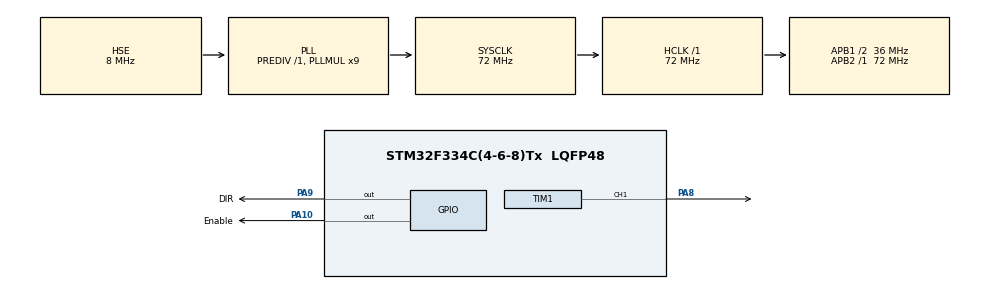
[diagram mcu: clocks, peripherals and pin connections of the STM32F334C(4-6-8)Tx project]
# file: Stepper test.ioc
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Mcu.Family=STM32F3
Mcu.Name=STM32F334C(4-6-8)Tx
Mcu.Package=LQFP48
NVIC.PriorityGroup=NVIC_PRIORITYGROUP_4
NVIC.TIM1_UP_TIM16_IRQn=true\:10\:0\:true\:false\:true\:true\:true\:true
PA10.GPIO_Label=Enable
PA10.Signal=GPIO_Output
PA13.Mode=Serial_Wire
PA13.Signal=SYS_JTMS-SWDIO
PA14.Mode=Serial_Wire
PA14.Signal=SYS_JTCK-SWCLK
PA8.Signal=S_TIM1_CH1
PA9.GPIO_Label=DIR
PA9.Signal=GPIO_Output
PF0\ /\ OSC_IN.Mode=HSE-External-Oscillator
PF0\ /\ OSC_IN.Signal=RCC_OSC_IN
PF1\ /\ OSC_OUT.Mode=HSE-External-Oscillator
PF1\ /\ OSC_OUT.Signal=RCC_OSC_OUT
ProjectManager.HeapSize=0x200
ProjectManager.StackSize=0x400
ProjectManager.TargetToolchain=MDK-ARM V5.32
RCC.AHBFreq_Value=72000000
RCC.APB1CLKDivider=RCC_HCLK_DIV2
RCC.APB1Freq_Value=36000000
RCC.APB1TimFreq_Value=72000000
RCC.APB2Freq_Value=72000000
RCC.APB2TimFreq_Value=72000000
RCC.CortexFreq_Value=72000000
RCC.HCLKFreq_Value=72000000
RCC.HSE_VALUE=8000000
RCC.HSI_VALUE=8000000
RCC.LSE_VALUE=32768
RCC.PLLMUL=RCC_PLL_MUL9
RCC.PLLSourceVirtual=RCC_PLLSOURCE_HSE
RCC.SYSCLKFreq_VALUE=72000000
RCC.SYSCLKSourceVirtual=RCC_SYSCLKSOURCE_PLLCLK
SH.S_TIM1_CH1.0=TIM1_CH1,PWM Generation1 CH1
TIM1.AutoReloadPreload=TIM_AUTORELOAD_PRELOAD_ENABLE
TIM1.Channel-PWM\ Generation1\ CH1=TIM_CHANNEL_1
TIM1.Period=7200
TIM1.Pulse-PWM\ Generation1\ CH1=3600
board=custom

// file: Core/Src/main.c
/* USER CODE BEGIN Header */
/**
  ******************************************************************************
  * @file           : main.c
  * @brief          : Main program body
  ******************************************************************************
  * @attention
  *
  * Copyright (c) 2023 STMicroelectronics.
  * All rights reserved.
  *
  * This software is licensed under terms that can be found in the LICENSE file
  * in the root directory of this software component.
  * If no LICENSE file comes with this software, it is provided AS-IS.
  *
  ******************************************************************************
  */
/* USER CODE END Header */
#include "main.h"
#include "tim.h"
#include "gpio.h"

/* USER CODE BEGIN Includes */
uint16_t Period, Pulse;
uint8_t En, Dir;
uint32_t i_count, steps, start;
uint16_t time;
/* USER CODE END Includes */

void SystemClock_Config(void);

int main(void)
{

  /* MCU Configuration--------------------------------------------------------*/

  /* Reset of all peripherals, Initializes the Flash interface and the Systick. */
  HAL_Init();

  /* Configure the system clock */
  SystemClock_Config();

  /* Initialize all configured peripherals */
  MX_GPIO_Init();
	HAL_GPIO_WritePin(Enable_GPIO_Port, Enable_Pin, GPIO_PIN_SET);
  MX_TIM1_Init();
  /* USER CODE BEGIN 2 */
	Period = 36000;
	time = 200;
  HAL_TIM_Base_Start_IT(&htim1);
  HAL_TIM_PWM_Start(&htim1, TIM_CHANNEL_1);
  /* USER CODE END 2 */

  /* Infinite loop */
  while (1)
  {

		if(start == 1) {
			if(En == 1) {
				HAL_GPIO_WritePin(Enable_GPIO_Port, Enable_Pin, GPIO_PIN_RESET);
			}
			else {
				HAL_GPIO_WritePin(Enable_GPIO_Port, Enable_Pin, GPIO_PIN_SET);
			}

			if(Dir == 1) {
				HAL_GPIO_WritePin(DIR_GPIO_Port, DIR_Pin, GPIO_PIN_RESET);
			}
			else {
				HAL_GPIO_WritePin(DIR_GPIO_Port, DIR_Pin, GPIO_PIN_SET);
			}

			HAL_Delay(time);
			if(Dir == 1) {
				Dir = 0;
			}
			else {
				Dir = 1;
			}

			if(Dir == 1) {
				HAL_GPIO_WritePin(DIR_GPIO_Port, DIR_Pin, GPIO_PIN_RESET);
			}
			else {
				HAL_GPIO_WritePin(DIR_GPIO_Port, DIR_Pin, GPIO_PIN_SET);
			}

			HAL_Delay(time);
			if(Dir == 1) {
				Dir = 0;
			}
			else {
				Dir = 1;
			}

			if(Dir == 1) {
				HAL_GPIO_WritePin(DIR_GPIO_Port, DIR_Pin, GPIO_PIN_RESET);
			}
			else {
				HAL_GPIO_WritePin(DIR_GPIO_Port, DIR_Pin, GPIO_PIN_SET);
			}
		}

		else {
			Dir = 0;
			En = 0;
			HAL_GPIO_WritePin(DIR_GPIO_Port, DIR_Pin, GPIO_PIN_SET);
			HAL_GPIO_WritePin(Enable_GPIO_Port, Enable_Pin, GPIO_PIN_SET);
		}

  }
}

void SystemClock_Config(void)
{
  RCC_OscInitTypeDef RCC_OscInitStruct = {0};
  RCC_ClkInitTypeDef RCC_ClkInitStruct = {0};
  RCC_PeriphCLKInitTypeDef PeriphClkInit = {0};

  /** Initializes the RCC Oscillators according to the specified parameters
  * in the RCC_OscInitTypeDef structure.
  */
  RCC_OscInitStruct.OscillatorType = RCC_OSCILLATORTYPE_HSE;
  RCC_OscInitStruct.HSEState = RCC_HSE_ON;
  RCC_OscInitStruct.HSEPredivValue = RCC_HSE_PREDIV_DIV1;
  RCC_OscInitStruct.HSIState = RCC_HSI_ON;
  RCC_OscInitStruct.PLL.PLLState = RCC_PLL_ON;
  RCC_OscInitStruct.PLL.PLLSource = RCC_PLLSOURCE_HSE;
  RCC_OscInitStruct.PLL.PLLMUL = RCC_PLL_MUL9;
  if (HAL_RCC_OscConfig(&RCC_OscInitStruct) != HAL_OK)
  {
    Error_Handler();
  }

  /** Initializes the CPU, AHB and APB buses clocks
  */
  RCC_ClkInitStruct.ClockType = RCC_CLOCKTYPE_HCLK|RCC_CLOCKTYPE_SYSCLK
                              |RCC_CLOCKTYPE_PCLK1|RCC_CLOCKTYPE_PCLK2;
  RCC_ClkInitStruct.SYSCLKSource = RCC_SYSCLKSOURCE_PLLCLK;
  RCC_ClkInitStruct.AHBCLKDivider = RCC_SYSCLK_DIV1;
  RCC_ClkInitStruct.APB1CLKDivider = RCC_HCLK_DIV2;
  RCC_ClkInitStruct.APB2CLKDivider = RCC_HCLK_DIV1;

  if (HAL_RCC_ClockConfig(&RCC_ClkInitStruct, FLASH_LATENCY_2) != HAL_OK)
  {
    Error_Handler();
  }
  PeriphClkInit.PeriphClockSelection = RCC_PERIPHCLK_TIM1;
  PeriphClkInit.Tim1ClockSelection = RCC_TIM1CLK_HCLK;
  if (HAL_RCCEx_PeriphCLKConfig(&PeriphClkInit) != HAL_OK)
  {
    Error_Handler();
  }
}

void Error_Handler(void)
{
  __disable_irq();
  while (1)
  {
  }
}
